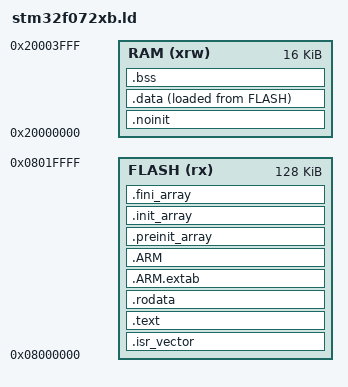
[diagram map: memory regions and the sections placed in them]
/* STM32F072xB: 128 KB flash, 16 KB SRAM; retained DFU state lives at the start of SRAM. */

ENTRY(Reset_Handler)

MEMORY
{
  FLASH (rx)  : ORIGIN = 0x08000000, LENGTH = 128K
  RAM   (xrw) : ORIGIN = 0x20000000, LENGTH = 16K
}

_estack = ORIGIN(RAM) + LENGTH(RAM);

SECTIONS
{
  .isr_vector :
  {
    . = ALIGN(4);
    KEEP(*(.isr_vector))
    . = ALIGN(4);
  } > FLASH

  .text :
  {
    . = ALIGN(4);
    *(.text)
    *(.text*)
    *(.glue_7)
    *(.glue_7t)
    KEEP(*(.init))
    KEEP(*(.fini))
    . = ALIGN(4);
  } > FLASH

  .rodata :
  {
    . = ALIGN(4);
    *(.rodata)
    *(.rodata*)
    . = ALIGN(4);
  } > FLASH

  .ARM.extab :
  {
    *(.ARM.extab* .gnu.linkonce.armextab.*)
  } > FLASH

  .ARM :
  {
    __exidx_start = .;
    *(.ARM.exidx*)
    __exidx_end = .;
  } > FLASH

  .preinit_array :
  {
    PROVIDE_HIDDEN(__preinit_array_start = .);
    KEEP(*(.preinit_array*))
    PROVIDE_HIDDEN(__preinit_array_end = .);
  } > FLASH

  .init_array :
  {
    PROVIDE_HIDDEN(__init_array_start = .);
    KEEP(*(SORT(.init_array.*)))
    KEEP(*(.init_array*))
    PROVIDE_HIDDEN(__init_array_end = .);
  } > FLASH

  .fini_array :
  {
    PROVIDE_HIDDEN(__fini_array_start = .);
    KEEP(*(SORT(.fini_array.*)))
    KEEP(*(.fini_array*))
    PROVIDE_HIDDEN(__fini_array_end = .);
  } > FLASH

  /* Excluded from startup copying/clearing and from the downward-growing stack. */
  .noinit ORIGIN(RAM) (NOLOAD) :
  {
    _snoinit = .;
    KEEP(*(.dfu_state .noinit .noinit.*))
    . = ALIGN(4);
    _enoinit = .;
  } > RAM

  _sidata = LOADADDR(.data);

  .data :
  {
    . = ALIGN(4);
    _sdata = .;
    *(.data)
    *(.data*)
    . = ALIGN(4);
    _edata = .;
  } > RAM AT > FLASH

  .bss :
  {
    . = ALIGN(4);
    _sbss = .;
    __bss_start__ = .;
    *(.bss)
    *(.bss*)
    *(COMMON)
    . = ALIGN(4);
    _ebss = .;
    __bss_end__ = .;
  } > RAM

  /DISCARD/ :
  {
    libc.a ( * )
    libm.a ( * )
    libgcc.a ( * )
  }
}
